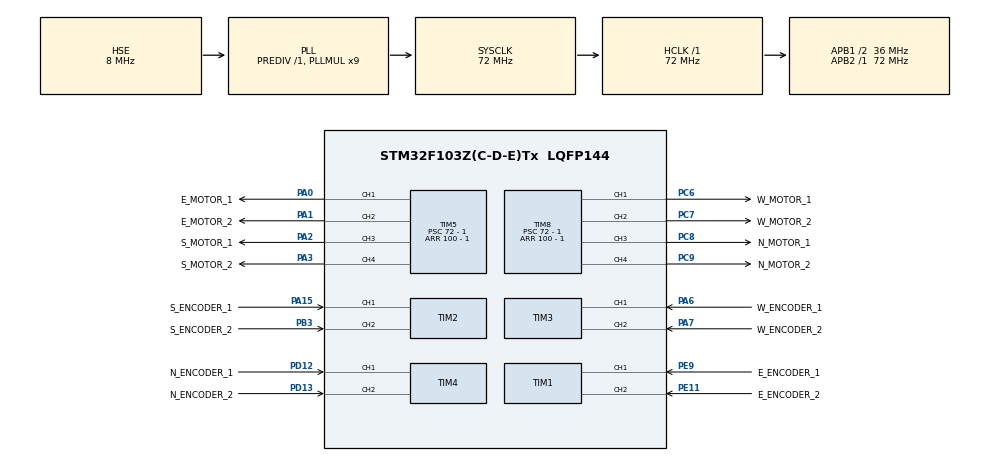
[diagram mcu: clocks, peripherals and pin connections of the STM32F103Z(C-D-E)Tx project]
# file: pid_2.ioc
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Mcu.Family=STM32F1
Mcu.Name=STM32F103Z(C-D-E)Tx
Mcu.Package=LQFP144
NVIC.PriorityGroup=NVIC_PRIORITYGROUP_4
OSC_IN.Mode=HSE-External-Oscillator
OSC_IN.Signal=RCC_OSC_IN
OSC_OUT.Mode=HSE-External-Oscillator
OSC_OUT.Signal=RCC_OSC_OUT
PA0-WKUP.GPIO_Label=E_MOTOR_1
PA0-WKUP.Signal=S_TIM5_CH1
PA1.GPIO_Label=E_MOTOR_2
PA1.Signal=S_TIM5_CH2
PA13.Mode=Serial_Wire
PA13.Signal=SYS_JTMS-SWDIO
PA14.Mode=Serial_Wire
PA14.Signal=SYS_JTCK-SWCLK
PA15.GPIO_Label=S_ENCODER_1
PA15.Signal=S_TIM2_CH1_ETR
PA2.GPIO_Label=S_MOTOR_1
PA2.Signal=S_TIM5_CH3
PA3.GPIO_Label=S_MOTOR_2
PA3.Signal=S_TIM5_CH4
PA6.GPIO_Label=W_ENCODER_1
PA6.Signal=S_TIM3_CH1
PA7.GPIO_Label=W_ENCODER_2
PA7.Signal=S_TIM3_CH2
PB3.GPIO_Label=S_ENCODER_2
PB3.Signal=S_TIM2_CH2
PC6.GPIO_Label=W_MOTOR_1
PC6.Signal=S_TIM8_CH1
PC7.GPIO_Label=W_MOTOR_2
PC7.Signal=S_TIM8_CH2
PC8.GPIO_Label=N_MOTOR_1
PC8.Signal=S_TIM8_CH3
PC9.GPIO_Label=N_MOTOR_2
PC9.Signal=S_TIM8_CH4
PD12.GPIO_Label=N_ENCODER_1
PD12.Signal=S_TIM4_CH1
PD13.GPIO_Label=N_ENCODER_2
PD13.Signal=S_TIM4_CH2
PE11.GPIO_Label=E_ENCODER_2
PE11.Signal=S_TIM1_CH2
PE9.GPIO_Label=E_ENCODER_1
PE9.Signal=S_TIM1_CH1
ProjectManager.HeapSize=0x200
ProjectManager.StackSize=0x400
ProjectManager.TargetToolchain=STM32CubeIDE
RCC.AHBFreq_Value=72000000
RCC.APB1CLKDivider=RCC_HCLK_DIV2
RCC.APB1Freq_Value=36000000
RCC.APB1TimFreq_Value=72000000
RCC.APB2Freq_Value=72000000
RCC.APB2TimFreq_Value=72000000
RCC.HCLKFreq_Value=72000000
RCC.PLLMUL=RCC_PLL_MUL9
RCC.PLLSourceVirtual=RCC_PLLSOURCE_HSE
RCC.SYSCLKFreq_VALUE=72000000
RCC.SYSCLKSource=RCC_SYSCLKSOURCE_PLLCLK
RCC.USBFreq_Value=72000000
SH.S_TIM1_CH1.0=TIM1_CH1,Encoder_Interface
SH.S_TIM1_CH2.0=TIM1_CH2,Encoder_Interface
SH.S_TIM2_CH1_ETR.0=TIM2_CH1,Encoder_Interface
SH.S_TIM2_CH2.0=TIM2_CH2,Encoder_Interface
SH.S_TIM3_CH1.0=TIM3_CH1,Encoder_Interface
SH.S_TIM3_CH2.0=TIM3_CH2,Encoder_Interface
SH.S_TIM4_CH1.0=TIM4_CH1,Encoder_Interface
SH.S_TIM4_CH2.0=TIM4_CH2,Encoder_Interface
SH.S_TIM5_CH1.0=TIM5_CH1,PWM Generation1 CH1
SH.S_TIM5_CH2.0=TIM5_CH2,PWM Generation2 CH2
SH.S_TIM5_CH3.0=TIM5_CH3,PWM Generation3 CH3
SH.S_TIM5_CH4.0=TIM5_CH4,PWM Generation4 CH4
SH.S_TIM8_CH1.0=TIM8_CH1,PWM Generation1 CH1
SH.S_TIM8_CH2.0=TIM8_CH2,PWM Generation2 CH2
SH.S_TIM8_CH3.0=TIM8_CH3,PWM Generation3 CH3
SH.S_TIM8_CH4.0=TIM8_CH4,PWM Generation4 CH4
TIM1.AutoReloadPreload=TIM_AUTORELOAD_PRELOAD_DISABLE
TIM2.AutoReloadPreload=TIM_AUTORELOAD_PRELOAD_DISABLE
TIM3.AutoReloadPreload=TIM_AUTORELOAD_PRELOAD_DISABLE
TIM4.AutoReloadPreload=TIM_AUTORELOAD_PRELOAD_DISABLE
TIM5.Channel-PWM\ Generation1\ CH1=TIM_CHANNEL_1
TIM5.Channel-PWM\ Generation2\ CH2=TIM_CHANNEL_2
TIM5.Channel-PWM\ Generation3\ CH3=TIM_CHANNEL_3
TIM5.Channel-PWM\ Generation4\ CH4=TIM_CHANNEL_4
TIM5.Period=100 - 1
TIM5.Prescaler=72 - 1
TIM8.Channel-PWM\ Generation1\ CH1=TIM_CHANNEL_1
TIM8.Channel-PWM\ Generation2\ CH2=TIM_CHANNEL_2
TIM8.Channel-PWM\ Generation3\ CH3=TIM_CHANNEL_3
TIM8.Channel-PWM\ Generation4\ CH4=TIM_CHANNEL_4
TIM8.Period=100 - 1
TIM8.Prescaler=72 - 1
VP_TIM5_VS_ClockSourceINT.Mode=Internal
VP_TIM8_VS_ClockSourceINT.Mode=Internal
board=custom

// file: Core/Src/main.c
/* USER CODE BEGIN Header */
/**
  ******************************************************************************
  * @file           : main.c
  * @brief          : Main program body
  ******************************************************************************
  * @attention
  *
  * Copyright (c) 2025 STMicroelectronics.
  * All rights reserved.
  *
  * This software is licensed under terms that can be found in the LICENSE file
  * in the root directory of this software component.
  * If no LICENSE file comes with this software, it is provided AS-IS.
  *
  ******************************************************************************
  */
/* USER CODE END Header */
#include "main.h"
#include "tim.h"
#include "gpio.h"

/* USER CODE BEGIN Includes */
#include "motor.h"
#include "encoder.h"
#include "mecanum.h"
#include "robot.h"
/* USER CODE END Includes */

void SystemClock_Config(void);

int main(void)
{

  /* MCU Configuration--------------------------------------------------------*/

  /* Reset of all peripherals, Initializes the Flash interface and the Systick. */
  HAL_Init();

  /* Configure the system clock */
  SystemClock_Config();

  /* Initialize all configured peripherals */
  MX_GPIO_Init();
  MX_TIM1_Init();
  MX_TIM2_Init();
  MX_TIM3_Init();
  MX_TIM4_Init();
  MX_TIM5_Init();
  MX_TIM8_Init();

  /* Infinite loop */
  while (1)
  {

  }
}

void SystemClock_Config(void)
{
  RCC_OscInitTypeDef RCC_OscInitStruct = {0};
  RCC_ClkInitTypeDef RCC_ClkInitStruct = {0};

  /** Initializes the RCC Oscillators according to the specified parameters
  * in the RCC_OscInitTypeDef structure.
  */
  RCC_OscInitStruct.OscillatorType = RCC_OSCILLATORTYPE_HSE;
  RCC_OscInitStruct.HSEState = RCC_HSE_ON;
  RCC_OscInitStruct.HSEPredivValue = RCC_HSE_PREDIV_DIV1;
  RCC_OscInitStruct.HSIState = RCC_HSI_ON;
  RCC_OscInitStruct.PLL.PLLState = RCC_PLL_ON;
  RCC_OscInitStruct.PLL.PLLSource = RCC_PLLSOURCE_HSE;
  RCC_OscInitStruct.PLL.PLLMUL = RCC_PLL_MUL9;
  if (HAL_RCC_OscConfig(&RCC_OscInitStruct) != HAL_OK)
  {
    Error_Handler();
  }

  /** Initializes the CPU, AHB and APB buses clocks
  */
  RCC_ClkInitStruct.ClockType = RCC_CLOCKTYPE_HCLK|RCC_CLOCKTYPE_SYSCLK
                              |RCC_CLOCKTYPE_PCLK1|RCC_CLOCKTYPE_PCLK2;
  RCC_ClkInitStruct.SYSCLKSource = RCC_SYSCLKSOURCE_PLLCLK;
  RCC_ClkInitStruct.AHBCLKDivider = RCC_SYSCLK_DIV1;
  RCC_ClkInitStruct.APB1CLKDivider = RCC_HCLK_DIV2;
  RCC_ClkInitStruct.APB2CLKDivider = RCC_HCLK_DIV1;

  if (HAL_RCC_ClockConfig(&RCC_ClkInitStruct, FLASH_LATENCY_2) != HAL_OK)
  {
    Error_Handler();
  }
}

void Error_Handler(void)
{
  __disable_irq();
  while (1)
  {
  }
}
